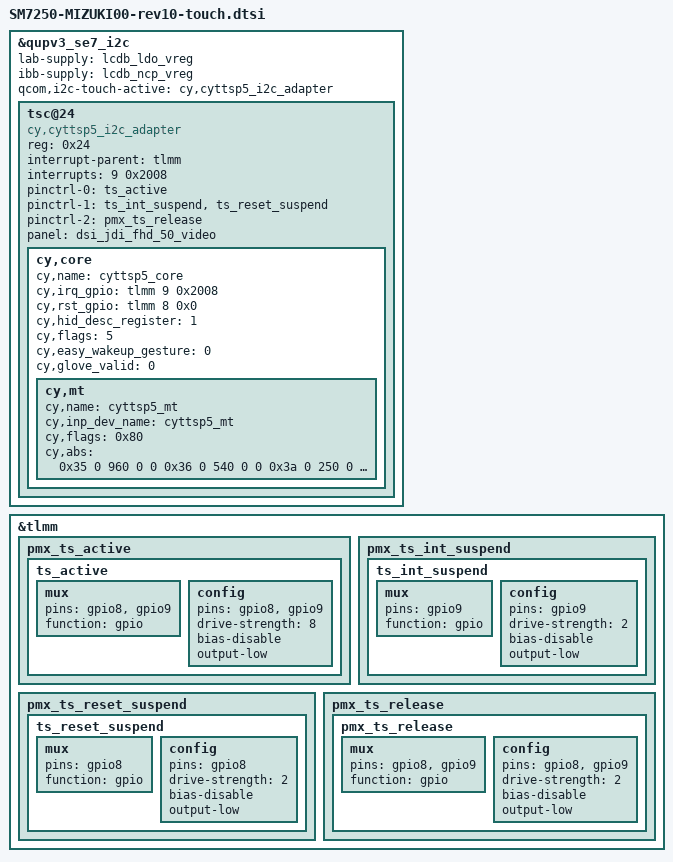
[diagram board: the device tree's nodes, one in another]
/*
 * This software is contributed or developed by KYOCERA Corporation.
 * (C) 2020 KYOCERA Corporation
 *
 * This program is free software; you can redistribute it and/or modify
 * it under the terms of the GNU General Public License version 2 and
 * only version 2 as published by the Free Software Foundation.
 *
 * This program is distributed in the hope that it will be useful,
 * but WITHOUT ANY WARRANTY; without even the implied warranty of
 * MERCHANTABILITY or FITNESS FOR A PARTICULAR PURPOSE.  See the
 * GNU General Public License for more details.
 */

&qupv3_se7_i2c {
	#address-cells = <1>;
	#size-cells = <0>;

	status = "ok";

	lab-supply = <&lcdb_ldo_vreg>;
	ibb-supply = <&lcdb_ncp_vreg>;

	qcom,i2c-touch-active = "cy,cyttsp5_i2c_adapter";

	tsc@24 {
		compatible = "cy,cyttsp5_i2c_adapter";
		reg = <0x24>;
		interrupt-parent = <&tlmm>;
		interrupts = <9 0x2008>;
		pinctrl-names = "pmx_ts_active", "pmx_ts_suspend",
				"pmx_ts_release";
		pinctrl-0 = <&ts_active>;
		pinctrl-1 = <&ts_int_suspend &ts_reset_suspend>;
		pinctrl-2 = <&pmx_ts_release>;

		panel = <&dsi_jdi_fhd_50_video>;

		cy,core {
			cy,name = "cyttsp5_core";

			cy,irq_gpio = <&tlmm 9 0x2008>;
			cy,rst_gpio = <&tlmm 8 0x0>;

			cy,hid_desc_register = <1>;
			cy,flags = <5>;
			cy,easy_wakeup_gesture = <0>;
			cy,glove_valid = <0>;

			cy,mt {
				cy,name = "cyttsp5_mt";
				cy,inp_dev_name = "cyttsp5_mt";
				cy,flags = <0x80>;
				cy,abs =
					<0x35 0 960 0 0
					0x36 0 540 0 0
					0x3a 0 250 0 0
					0xffff 0 255 0 0
					0x39 0 15 0 0
					0x30 0 20 0 0
					0x31 0 20 0 0
					0x34 0xffffff81 127 0 0
					0x19 0 255 0 0>;
			};
		};
	};

};

&tlmm {
		pmx_ts_active {
			ts_active: ts_active {
				mux {
					pins = "gpio8", "gpio9";
					function = "gpio";
				};

				config {
					pins = "gpio8", "gpio9";
					drive-strength = <8>;
//					bias-pull-up;
					bias-disable;
					output-low;
				};
			};
		};

		pmx_ts_int_suspend {
			ts_int_suspend: ts_int_suspend {
				mux {
					pins = "gpio9";
					function = "gpio";
				};

				config {
					pins = "gpio9";
					drive-strength = <2>;
//					bias-pull-down;
					bias-disable;
					output-low;
				};
			};
		};

		pmx_ts_reset_suspend {
			ts_reset_suspend: ts_reset_suspend {
				mux {
					pins = "gpio8";
					function = "gpio";
				};

				config {
					pins = "gpio8";
					drive-strength = <2>;
//					bias-pull-down;
					bias-disable;
					output-low;
				};
			};
		};

		pmx_ts_release {
			pmx_ts_release: pmx_ts_release {
				mux {
					pins = "gpio8", "gpio9";
					function = "gpio";
				};

				config {
					pins = "gpio8", "gpio9";
					drive-strength = <2>;
					bias-disable;
					output-low;
				};
			};
		};
};
